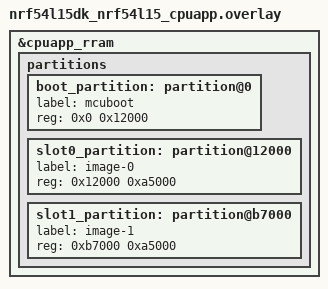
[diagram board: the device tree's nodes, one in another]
/*
 * Copyright (c) 2025 Nordic Semiconductor ASA
 *
 * SPDX-License-Identifier: LicenseRef-Nordic-5-Clause
 */

/delete-node/ &boot_partition;
/delete-node/ &slot0_partition;
/delete-node/ &slot1_partition;

&cpuapp_rram {
	partitions {
		boot_partition: partition@0 {
			label = "mcuboot";
			reg = < 0x0 0x12000 >;
		};

		slot0_partition: partition@12000 {
			label = "image-0";
			reg = < 0x12000 0xa5000 >;
		};

		slot1_partition: partition@b7000 {
			label = "image-1";
			reg = < 0xb7000 0xa5000 >;
		};
	};
};
